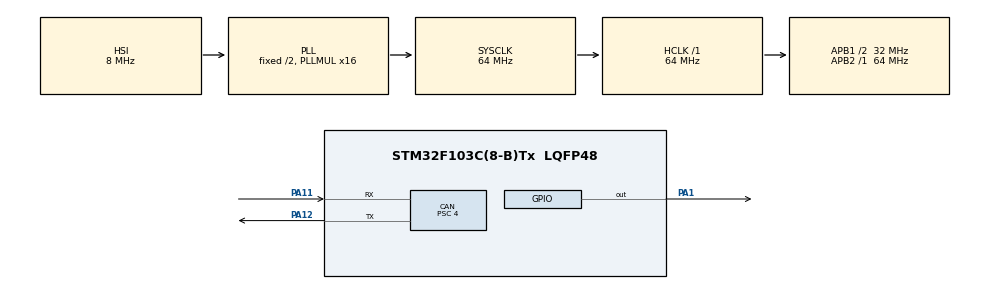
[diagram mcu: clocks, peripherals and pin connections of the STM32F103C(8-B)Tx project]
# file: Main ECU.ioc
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CAN.BS1=CAN_BS1_13TQ
CAN.BS2=CAN_BS2_2TQ
CAN.CalculateBaudRate=500000
CAN.CalculateTimeBit=2000
CAN.CalculateTimeQuantum=125.0
CAN.Prescaler=4
Mcu.Family=STM32F1
Mcu.Name=STM32F103C(8-B)Tx
Mcu.Package=LQFP48
NVIC.PriorityGroup=NVIC_PRIORITYGROUP_4
NVIC.TIM1_UP_IRQn=true\:15\:0\:false\:false\:true\:false\:true\:true
NVIC.TimeBase=TIM1_UP_IRQn
NVIC.TimeBaseIP=TIM1
NVIC.USB_HP_CAN1_TX_IRQn=true\:7\:0\:true\:false\:true\:true\:true\:true
NVIC.USB_LP_CAN1_RX0_IRQn=true\:7\:0\:true\:false\:true\:true\:true\:true
PA1.Signal=GPIO_Output
PA11.Mode=CAN_Activate
PA11.Signal=CAN_RX
PA12.Mode=CAN_Activate
PA12.Signal=CAN_TX
PA13.Mode=Serial_Wire
PA13.Signal=SYS_JTMS-SWDIO
PA14.Mode=Serial_Wire
PA14.Signal=SYS_JTCK-SWCLK
ProjectManager.HeapSize=0x200
ProjectManager.StackSize=0x400
ProjectManager.TargetToolchain=STM32CubeIDE
RCC.AHBFreq_Value=64000000
RCC.APB1CLKDivider=RCC_HCLK_DIV2
RCC.APB1Freq_Value=32000000
RCC.APB1TimFreq_Value=64000000
RCC.APB2Freq_Value=64000000
RCC.APB2TimFreq_Value=64000000
RCC.HCLKFreq_Value=64000000
RCC.PLLMUL=RCC_PLL_MUL16
RCC.SYSCLKFreq_VALUE=64000000
RCC.SYSCLKSource=RCC_SYSCLKSOURCE_PLLCLK
RCC.USBFreq_Value=64000000
RTC.Format=RTC_FORMAT_BIN
VP_RTC_VS_RTC_Activate.Mode=RTC_Enabled
VP_RTC_VS_RTC_Calendar.Mode=RTC_Calendar
VP_SYS_VS_tim1.Mode=TIM1
board=custom

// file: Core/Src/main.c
/* USER CODE BEGIN Header */
/**
  ******************************************************************************
  * @file           : main.c
  * @brief          : Main program body
  ******************************************************************************
  * @attention
  *
  * Copyright (c) 2025 STMicroelectronics.
  * All rights reserved.
  *
  * This software is licensed under terms that can be found in the LICENSE file
  * in the root directory of this software component.
  * If no LICENSE file comes with this software, it is provided AS-IS.
  *
  ******************************************************************************
  */
/* USER CODE END Header */
#include "main.h"

/* USER CODE BEGIN Includes */
#include "TaskHandle.h"
/* USER CODE END Includes */

CAN_HandleTypeDef hcan;

RTC_HandleTypeDef hrtc;

void SystemClock_Config(void);
static void MX_GPIO_Init(void);
static void MX_CAN_Init(void);
static void MX_RTC_Init(void);
/* USER CODE BEGIN PFP */
void CAN_Filter_Config(void);
/* USER CODE END PFP */

int main(void)
{

  /* MCU Configuration--------------------------------------------------------*/

  /* Reset of all peripherals, Initializes the Flash interface and the Systick. */
  HAL_Init();

  /* Configure the system clock */
  SystemClock_Config();

  /* Initialize all configured peripherals */
  MX_GPIO_Init();
  MX_CAN_Init();
  MX_RTC_Init();
  /* USER CODE BEGIN 2 */

  /* configure three banks */
  CAN_Filter_Config();

  /* Start CAN peripheral and notifications */
  HAL_CAN_Start(&hcan);
  HAL_CAN_ActivateNotification(&hcan, CAN_IT_RX_FIFO0_MSG_PENDING);

  /** Initialize FreeRTOS tasks **/
  FreeRTOS_Init();

  /** Start scheduler **/
  Start_Scheduler();

  /* USER CODE END 2 */

  /* Infinite loop */
  while (1)
  {

  }
}

void SystemClock_Config(void)
{
  RCC_OscInitTypeDef RCC_OscInitStruct = {0};
  RCC_ClkInitTypeDef RCC_ClkInitStruct = {0};
  RCC_PeriphCLKInitTypeDef PeriphClkInit = {0};

  /** Initializes the RCC Oscillators according to the specified parameters
  * in the RCC_OscInitTypeDef structure.
  */
  RCC_OscInitStruct.OscillatorType = RCC_OSCILLATORTYPE_HSI|RCC_OSCILLATORTYPE_LSI;
  RCC_OscInitStruct.HSIState = RCC_HSI_ON;
  RCC_OscInitStruct.HSICalibrationValue = RCC_HSICALIBRATION_DEFAULT;
  RCC_OscInitStruct.LSIState = RCC_LSI_ON;
  RCC_OscInitStruct.PLL.PLLState = RCC_PLL_ON;
  RCC_OscInitStruct.PLL.PLLSource = RCC_PLLSOURCE_HSI_DIV2;
  RCC_OscInitStruct.PLL.PLLMUL = RCC_PLL_MUL16;
  if (HAL_RCC_OscConfig(&RCC_OscInitStruct) != HAL_OK)
  {
    Error_Handler();
  }

  /** Initializes the CPU, AHB and APB buses clocks
  */
  RCC_ClkInitStruct.ClockType = RCC_CLOCKTYPE_HCLK|RCC_CLOCKTYPE_SYSCLK
                              |RCC_CLOCKTYPE_PCLK1|RCC_CLOCKTYPE_PCLK2;
  RCC_ClkInitStruct.SYSCLKSource = RCC_SYSCLKSOURCE_PLLCLK;
  RCC_ClkInitStruct.AHBCLKDivider = RCC_SYSCLK_DIV1;
  RCC_ClkInitStruct.APB1CLKDivider = RCC_HCLK_DIV2;
  RCC_ClkInitStruct.APB2CLKDivider = RCC_HCLK_DIV1;

  if (HAL_RCC_ClockConfig(&RCC_ClkInitStruct, FLASH_LATENCY_2) != HAL_OK)
  {
    Error_Handler();
  }
  PeriphClkInit.PeriphClockSelection = RCC_PERIPHCLK_RTC;
  PeriphClkInit.RTCClockSelection = RCC_RTCCLKSOURCE_LSI;
  if (HAL_RCCEx_PeriphCLKConfig(&PeriphClkInit) != HAL_OK)
  {
    Error_Handler();
  }
}

static void MX_CAN_Init(void)
{

  hcan.Instance = CAN1;
  hcan.Init.Prescaler = 4;
  hcan.Init.Mode = CAN_MODE_NORMAL;
  hcan.Init.SyncJumpWidth = CAN_SJW_1TQ;
  hcan.Init.TimeSeg1 = CAN_BS1_13TQ;
  hcan.Init.TimeSeg2 = CAN_BS2_2TQ;
  hcan.Init.TimeTriggeredMode = DISABLE;
  hcan.Init.AutoBusOff = DISABLE;
  hcan.Init.AutoWakeUp = DISABLE;
  hcan.Init.AutoRetransmission = DISABLE;
  hcan.Init.ReceiveFifoLocked = DISABLE;
  hcan.Init.TransmitFifoPriority = DISABLE;
  if (HAL_CAN_Init(&hcan) != HAL_OK)
  {
    Error_Handler();
  }

}

static void MX_RTC_Init(void)
{

  RTC_TimeTypeDef sTime = {0};
  RTC_DateTypeDef DateToUpdate = {0};

  /** Initialize RTC Only
  */
  hrtc.Instance = RTC;
  hrtc.Init.AsynchPrediv = RTC_AUTO_1_SECOND;
  hrtc.Init.OutPut = RTC_OUTPUTSOURCE_ALARM;
  if (HAL_RTC_Init(&hrtc) != HAL_OK)
  {
    Error_Handler();
  }

  /** Initialize RTC and set the Time and Date
  */
  sTime.Hours = 0;
  sTime.Minutes = 0;
  sTime.Seconds = 0;

  if (HAL_RTC_SetTime(&hrtc, &sTime, RTC_FORMAT_BIN) != HAL_OK)
  {
    Error_Handler();
  }
  DateToUpdate.WeekDay = RTC_WEEKDAY_MONDAY;
  DateToUpdate.Month = RTC_MONTH_JANUARY;
  DateToUpdate.Date = 1;
  DateToUpdate.Year = 0;

  if (HAL_RTC_SetDate(&hrtc, &DateToUpdate, RTC_FORMAT_BIN) != HAL_OK)
  {
    Error_Handler();
  }

}

static void MX_GPIO_Init(void)
{
  GPIO_InitTypeDef GPIO_InitStruct = {0};

  /* GPIO Ports Clock Enable */
  __HAL_RCC_GPIOA_CLK_ENABLE();

  /*Configure GPIO pin Output Level */
  HAL_GPIO_WritePin(GPIOA, GPIO_PIN_1, GPIO_PIN_RESET);

  /*Configure GPIO pin : PA1 */
  GPIO_InitStruct.Pin = GPIO_PIN_1;
  GPIO_InitStruct.Mode = GPIO_MODE_OUTPUT_PP;
  GPIO_InitStruct.Pull = GPIO_NOPULL;
  GPIO_InitStruct.Speed = GPIO_SPEED_FREQ_LOW;
  HAL_GPIO_Init(GPIOA, &GPIO_InitStruct);

}

/* USER CODE BEGIN 4 */

void CAN_Filter_Config(void)
{
    CAN_FilterTypeDef filter;

    /* Filter for CAN_ID_1 in bank 0 */
    filter.FilterBank           = 0;
    filter.FilterMode           = CAN_FILTERMODE_IDLIST;
    filter.FilterScale          = CAN_FILTERSCALE_32BIT;
    filter.FilterFIFOAssignment = CAN_FILTER_FIFO0;
    filter.FilterActivation     = ENABLE;

    /* Position standard ID at bits 21..31 */
    filter.FilterIdHigh   = (uint16_t)(UDS_REQUEST_ID << 5);       /* high 16 bits of 32-bit ID */
    filter.FilterIdLow    =  0x0000;                         /* low 16 bits */
    filter.FilterMaskIdHigh = 0xFFFF;                        /* unused in IDLIST */
    filter.FilterMaskIdLow    = 0xFFFF;
    HAL_CAN_ConfigFilter(&hcan, &filter);

    /* Filter for CAN_ID_2 in bank 1 */
    filter.FilterBank = 1;
    filter.FilterIdHigh   = (uint16_t)(SENSOR_DIST_ID << 5);
    filter.FilterIdLow    =  0x0000;
    HAL_CAN_ConfigFilter(&hcan, &filter);

    /* Filter for CAN_ID_3 in bank 2 */
    filter.FilterBank = 2;
    filter.FilterIdHigh   = (uint16_t)(SENSOR_TEMP_ID << 5);
    filter.FilterIdLow    =  0x0000;
    HAL_CAN_ConfigFilter(&hcan, &filter);

    /* Filter for CAN_ID_4 in bank 3 */
    filter.FilterBank = 3;
    filter.FilterIdHigh   = (uint16_t)(SPEED_ID << 5);
    filter.FilterIdLow    =  0x0000;
    HAL_CAN_ConfigFilter(&hcan, &filter);
}

/* USER CODE END 4 */

void HAL_TIM_PeriodElapsedCallback(TIM_HandleTypeDef *htim)
{
  if (htim->Instance == TIM1) {
    HAL_IncTick();
  }
}

void Error_Handler(void)
{
  __disable_irq();
  while (1)
  {
  }
}
